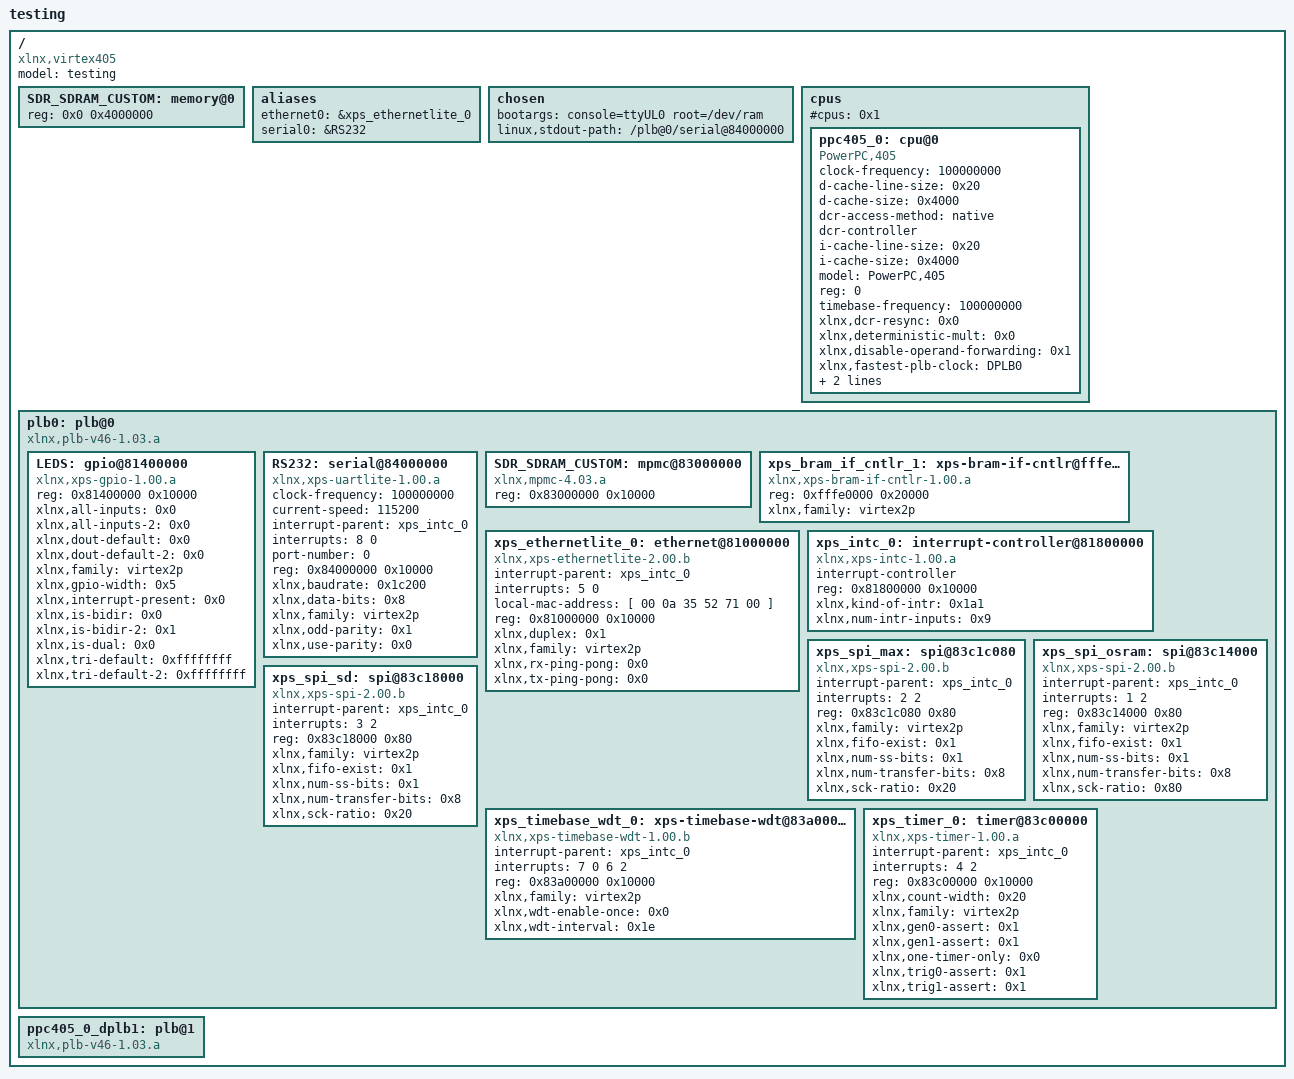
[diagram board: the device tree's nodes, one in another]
/*
 * Device Tree Generator version: 1.3
 *
 * (C) Copyright 2007-2008 Xilinx, Inc.
 * (C) Copyright 2007-2009 Michal Simek
 *
 * Michal SIMEK <monstr@monstr.eu>
 *
 * This program is free software; you can redistribute it and/or
 * modify it under the terms of the GNU General Public License as
 * published by the Free Software Foundation; either version 2 of
 * the License, or (at your option) any later version.
 *
 * This program is distributed in the hope that it will be useful,
 * but WITHOUT ANY WARRANTY; without even the implied warranty of
 * MERCHANTABILITY or FITNESS FOR A PARTICULAR PURPOSE. See the
 * GNU General Public License for more details.
 *
 * You should have received a copy of the GNU General Public License
 * along with this program; if not, write to the Free Software
 * Foundation, Inc., 59 Temple Place, Suite 330, Boston,
 * MA 02111-1307 USA
 *
 * CAUTION: This file is automatically generated by libgen.
 * Version: Xilinx EDK 10.1.03 EDK_K_SP3.6
 *
 * XPS project directory: xc2p_pe1
 */

/dts-v1/;
/ {
	#address-cells = <1>;
	#size-cells = <1>;
	compatible = "xlnx,virtex405", "xlnx,virtex";
	model = "testing";
	SDR_SDRAM_CUSTOM: memory@0 {
		device_type = "memory";
		reg = < 0x0 0x4000000 >;
	} ;
	aliases {
		ethernet0 = &xps_ethernetlite_0;
		serial0 = &RS232;
	} ;
	chosen {
		bootargs = "console=ttyUL0 root=/dev/ram";
		linux,stdout-path = "/plb@0/serial@84000000";
	} ;
	cpus {
		#address-cells = <1>;
		#cpus = <0x1>;
		#size-cells = <0>;
		ppc405_0: cpu@0 {
			clock-frequency = <100000000>;
			compatible = "PowerPC,405", "ibm,ppc405";
			d-cache-line-size = <0x20>;
			d-cache-size = <0x4000>;
			dcr-access-method = "native";
			dcr-controller ;
			device_type = "cpu";
			i-cache-line-size = <0x20>;
			i-cache-size = <0x4000>;
			model = "PowerPC,405";
			reg = <0>;
			timebase-frequency = <100000000>;
			xlnx,dcr-resync = <0x0>;
			xlnx,deterministic-mult = <0x0>;
			xlnx,disable-operand-forwarding = <0x1>;
			xlnx,fastest-plb-clock = "DPLB0";
			xlnx,generate-plb-timespecs = <0x1>;
			xlnx,mmu-enable = <0x1>;
		} ;
	} ;
	plb0: plb@0 {
		#address-cells = <1>;
		#size-cells = <1>;
		compatible = "xlnx,plb-v46-1.03.a", "xlnx,plb-v46-1.00.a", "simple-bus";
		ranges ;
		LEDS: gpio@81400000 {
			compatible = "xlnx,xps-gpio-1.00.a";
			reg = < 0x81400000 0x10000 >;
			xlnx,all-inputs = <0x0>;
			xlnx,all-inputs-2 = <0x0>;
			xlnx,dout-default = <0x0>;
			xlnx,dout-default-2 = <0x0>;
			xlnx,family = "virtex2p";
			xlnx,gpio-width = <0x5>;
			xlnx,interrupt-present = <0x0>;
			xlnx,is-bidir = <0x0>;
			xlnx,is-bidir-2 = <0x1>;
			xlnx,is-dual = <0x0>;
			xlnx,tri-default = <0xffffffff>;
			xlnx,tri-default-2 = <0xffffffff>;
		} ;
		RS232: serial@84000000 {
			clock-frequency = <100000000>;
			compatible = "xlnx,xps-uartlite-1.00.a";
			current-speed = <115200>;
			device_type = "serial";
			interrupt-parent = <&xps_intc_0>;
			interrupts = < 8 0 >;
			port-number = <0>;
			reg = < 0x84000000 0x10000 >;
			xlnx,baudrate = <0x1c200>;
			xlnx,data-bits = <0x8>;
			xlnx,family = "virtex2p";
			xlnx,odd-parity = <0x1>;
			xlnx,use-parity = <0x0>;
		} ;
		SDR_SDRAM_CUSTOM: mpmc@83000000 {
			#address-cells = <1>;
			#size-cells = <1>;
			compatible = "xlnx,mpmc-4.03.a";
			ranges ;
			reg = < 0x83000000 0x10000 >;
		} ;
		xps_bram_if_cntlr_1: xps-bram-if-cntlr@fffe0000 {
			compatible = "xlnx,xps-bram-if-cntlr-1.00.a";
			reg = < 0xfffe0000 0x20000 >;
			xlnx,family = "virtex2p";
		} ;
		xps_ethernetlite_0: ethernet@81000000 {
			compatible = "xlnx,xps-ethernetlite-2.00.b", "xlnx,xps-ethernetlite-1.00.a";
			device_type = "network";
			interrupt-parent = <&xps_intc_0>;
			interrupts = < 5 0 >;
			local-mac-address = [ 00 0a 35 52 71 00 ];
			reg = < 0x81000000 0x10000 >;
			xlnx,duplex = <0x1>;
			xlnx,family = "virtex2p";
			xlnx,rx-ping-pong = <0x0>;
			xlnx,tx-ping-pong = <0x0>;
		} ;
		xps_intc_0: interrupt-controller@81800000 {
			#interrupt-cells = <0x2>;
			compatible = "xlnx,xps-intc-1.00.a";
			interrupt-controller ;
			reg = < 0x81800000 0x10000 >;
			xlnx,kind-of-intr = <0x1a1>;
			xlnx,num-intr-inputs = <0x9>;
		} ;
		xps_spi_max: spi@83c1c080 {
			compatible = "xlnx,xps-spi-2.00.b", "xlnx,xps-spi-2.00.a";
			interrupt-parent = <&xps_intc_0>;
			interrupts = < 2 2 >;
			reg = < 0x83c1c080 0x80 >;
			xlnx,family = "virtex2p";
			xlnx,fifo-exist = <0x1>;
			xlnx,num-ss-bits = <0x1>;
			xlnx,num-transfer-bits = <0x8>;
			xlnx,sck-ratio = <0x20>;
		} ;
		xps_spi_osram: spi@83c14000 {
			compatible = "xlnx,xps-spi-2.00.b", "xlnx,xps-spi-2.00.a";
			interrupt-parent = <&xps_intc_0>;
			interrupts = < 1 2 >;
			reg = < 0x83c14000 0x80 >;
			xlnx,family = "virtex2p";
			xlnx,fifo-exist = <0x1>;
			xlnx,num-ss-bits = <0x1>;
			xlnx,num-transfer-bits = <0x8>;
			xlnx,sck-ratio = <0x80>;
		} ;
		xps_spi_sd: spi@83c18000 {
			compatible = "xlnx,xps-spi-2.00.b", "xlnx,xps-spi-2.00.a";
			interrupt-parent = <&xps_intc_0>;
			interrupts = < 3 2 >;
			reg = < 0x83c18000 0x80 >;
			xlnx,family = "virtex2p";
			xlnx,fifo-exist = <0x1>;
			xlnx,num-ss-bits = <0x1>;
			xlnx,num-transfer-bits = <0x8>;
			xlnx,sck-ratio = <0x20>;
		} ;
		xps_timebase_wdt_0: xps-timebase-wdt@83a00000 {
			compatible = "xlnx,xps-timebase-wdt-1.00.b";
			interrupt-parent = <&xps_intc_0>;
			interrupts = < 7 0 6 2 >;
			reg = < 0x83a00000 0x10000 >;
			xlnx,family = "virtex2p";
			xlnx,wdt-enable-once = <0x0>;
			xlnx,wdt-interval = <0x1e>;
		} ;
		xps_timer_0: timer@83c00000 {
			compatible = "xlnx,xps-timer-1.00.a";
			interrupt-parent = <&xps_intc_0>;
			interrupts = < 4 2 >;
			reg = < 0x83c00000 0x10000 >;
			xlnx,count-width = <0x20>;
			xlnx,family = "virtex2p";
			xlnx,gen0-assert = <0x1>;
			xlnx,gen1-assert = <0x1>;
			xlnx,one-timer-only = <0x0>;
			xlnx,trig0-assert = <0x1>;
			xlnx,trig1-assert = <0x1>;
		} ;
	} ;
	ppc405_0_dplb1: plb@1 {
		#address-cells = <1>;
		#size-cells = <1>;
		compatible = "xlnx,plb-v46-1.03.a", "xlnx,plb-v46-1.00.a", "simple-bus";
		ranges ;
	} ;
} ;
